# CY8C5868AXI_LP032 register map
File version: 0.1
CY8C58LP
Registers are 8-bit, read-write, no defined reset value unless marked. A register's access mark holds for its fields unless they carry their own. Offsets are from the block's base; lines under a group give offsets from that group; [hi:lo] are bit positions; {n}, {i} and the like mark numbered series; 'fields as' and 'values as' point back to an identical list; <NAME> marks a mode.

## Memory map
0x00000000 ADC_SAR_Seq_SAR — SAR ADC
0x00000000 ProbeUART — UART
0x00000000 LED_Status

## ADC_SAR_Seq_SAR — SAR ADC
Base 0x00000000
0x40004616 SAR_TR0 — SAR trim register
{0x40005908+i} SAR_CSR{i} (i=0..6) — SAR status and control register {i}
0x40005B28 SAR_SW0 — SAR Analog Routing Register 0
{0x40005B28+i} SAR_SW{i} (i=2..4) — SAR Analog Routing Register {i}
0x40005B2E SAR_SW6 — SAR Analog Routing Register 6
0x40005B2F SAR_CLK — SAR Clock Selection Register
0x40005BA2 SAR_WRK 16-bit — SAR working register

## ProbeUART — UART
Base 0x00000000
0x40006527 RX_ProbeUART_RX_ADDRESS1 — RX Address1 Register
0x40006537 RX_ProbeUART_RX_ADDRESS2 — RX Address2 Register
0x40006547 RX_ProbeUART_RX_DATA — RX Data Register
0x40006548 TX_ProbeUART_TX_DATA — TX Data Register
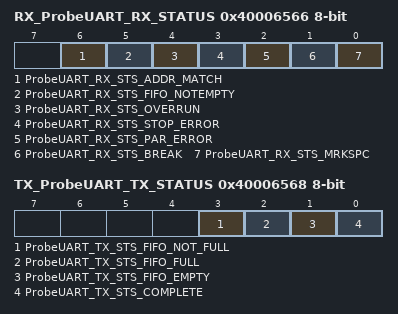
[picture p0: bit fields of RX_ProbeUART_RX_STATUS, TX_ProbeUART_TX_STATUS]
0x40006566 RX_ProbeUART_RX_STATUS — RX status register
  [6] ProbeUART_RX_STS_ADDR_MATCH ro, [5] ProbeUART_RX_STS_FIFO_NOTEMPTY ro, [4] ProbeUART_RX_STS_OVERRUN ro, [3] ProbeUART_RX_STS_STOP_ERROR ro, [2] ProbeUART_RX_STS_PAR_ERROR ro, [1] ProbeUART_RX_STS_BREAK ro, [0] ProbeUART_RX_STS_MRKSPC ro
0x40006568 TX_ProbeUART_TX_STATUS — TX status register
  [3] ProbeUART_TX_STS_FIFO_NOT_FULL ro, [2] ProbeUART_TX_STS_FIFO_FULL ro, [1] ProbeUART_TX_STS_FIFO_EMPTY ro, [0] ProbeUART_TX_STS_COMPLETE ro

## LED_Status
Base 0x00000000
0x40006471 LED_Status_CONTROL_REG
